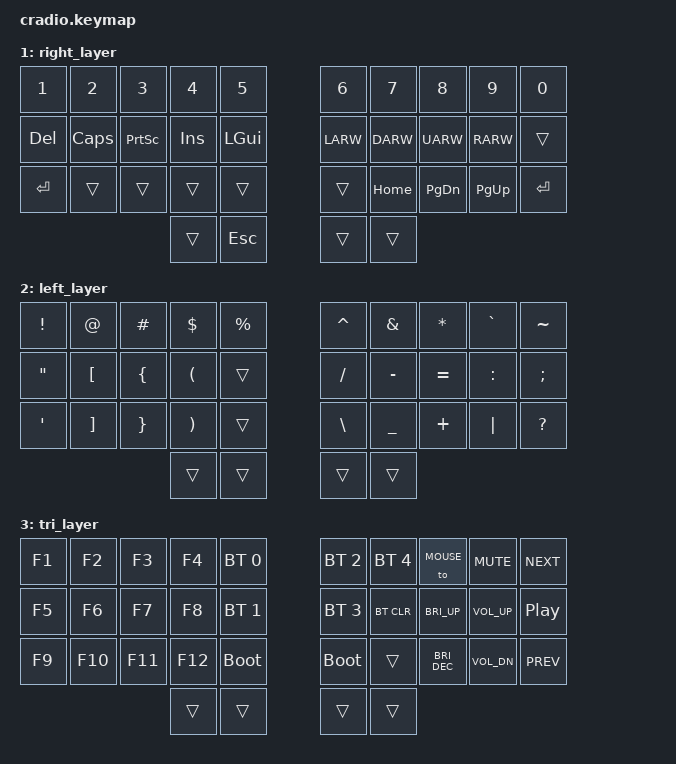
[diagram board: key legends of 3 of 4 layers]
#include <behaviors.dtsi>
#include <dt-bindings/zmk/keys.h>
#include <dt-bindings/zmk/bt.h>
#include <dt-bindings/zmk/mouse.h>

#include "../zmk-nodefree-config/helper.h"
#include "../zmk-nodefree-config/keypos_def/keypos_34keys.h"

#define HRML(k2,k3,k4) &ht LALT k2  &ht LCTRL k3  &ht LGUI k4
#define HRMR(k1,k2,k3) &ht RGUI k1  &ht RCTRL k2  &ht RALT k3
#define WHRML(k2,k3,k4) &ht LALT k2  &ht LGUI k3  &ht LCTRL k4
#define WHRMR(k1,k2,k3) &ht RCTRL k1  &ht RGUI k2  &ht RALT k3

#define WIN 0
#define RIG 1
#define LEF 2
#define TRI 3
#define MOUSE 4

/* layer and key shortcuts */

/ {
  combos {
    compatible = "zmk,combos";
    combo_tab {
      timeout-ms = <50>;
	    key-positions = <1 2>;
      bindings = <&kp TAB>;
     };
    combo_esc {
      timeout-ms = <50>;
	    key-positions = <11 12>;
      bindings = <&kp ESC>;
     };
     combo_lalt {
      timeout-ms = <50>;
      key-positions = <0 1>;
      bindings = <&sk LALT>;
     };
    combo_lctrl {
      timeout-ms = <50>;
	    key-positions = <10 11>;
      bindings = <&sk LCTRL>;
     };
     combo_lgui {
      timeout-ms = <50>;
	    key-positions = <20 21>;
      bindings = <&sk LGUI>;
     };
     combo_setting {
       timeout-ms = <50>;
	     key-positions = <20 21 22>;
       bindings = <&mo 4>;
     };
     combo_rsetting {
       timeout-ms = <50>;
	 key-positions = <27 28 29>;
       bindings = <&mo 4>;
     };
     combo_del {
      timeout-ms = <50>;
	    key-positions = <7 8>;
      bindings = <&kp DELETE>;
     };
     combo_back_space {
      timeout-ms = <50>;
	    key-positions = <17 18>;
      bindings = <&kp BSPC>;
     };
     combo_enter {
      timeout-ms = <50>;
	    key-positions = <27 28>;
      bindings = <&kp RETURN>;
     };
     combo_ralt {
      timeout-ms = <50>;
      key-positions = <8 9>;
      bindings = <&sk RALT>;
     };
     combo_rctrl {
      timeout-ms = <50>;
      key-positions = <18 19>;
      bindings = <&sk RCTRL>;
     };
     combo_rgui {
      timeout-ms = <50>;
	    key-positions = <28 29>;
      bindings = <&sk RGUI>;
     };
     combo_slash {
      timeout-ms = <50>;
	    key-positions = <12 13>;
      bindings = <&kp FSLH>;
     };
     combo_alt_h {
      timeout-ms = <50>;
	    key-positions = <14 24>;
      bindings = <&kp LA(H)>;
     };
     combo_semi {
      timeout-ms = <50>;
	    key-positions = <6 7>;
      bindings = <&kp SEMI>;
     };
     combo_col {
      timeout-ms = <50>;
	    key-positions = <16 17>;
      bindings = <&kp COLON>;
     };
  };

  behaviors {
        ht: hold_tap {
            label = "hold_tap";
            compatible = "zmk,behavior-hold-tap";
            #binding-cells = <2>;
            flavor = "tap-preferred";
            tapping-term-ms = <220>;
            quick-tap-ms = <150>;
            global-quick-tap;
            bindings = <&kp>, <&kp>;
        };
    };

   conditional_layers {
        compatible = "zmk,conditional-layers";
        tri_layer {
            if-layers = <RIG LEF>;
            then-layer = <TRI>;
        };
    };

  keymap {
      compatible = "zmk,keymap";
                
        default_layer {
            bindings = <
        //╭──────────┬──────────┬──────────┬──────────┬──────────╮   ╭──────────┬──────────┬──────────┬──────────┬──────────╮
        //│  Q       │  W       │  E       │  R       │  T       │   │  Y       │  U       │  I       │  O       │  P       │
            &kp Q      WHRML(W ,   E  ,       R  )       &kp T          &kp Y     WHRMR( U,   I ,   O )  &kp P
        //├──────────┼──────────┼──────────┼──────────┼──────────┤   ├──────────┼──────────┼──────────┼──────────┼──────────┤
        //│  A       │  S       │  D       │  F       │  G       │   │  H       │  J       │  K       │  L       │BACKSPACE │
            &kp A        &kp S     &kp  D     &kp  F     &kp G          &kp H      &kp J      &kp  K    &kp L      &kp BSPC
        //├──────────┼──────────┼──────────┼──────────┼──────────┤   ├──────────┼──────────┼──────────┼──────────┼──────────┤
        //│  Z       │  X       │  C       │  V       │  B       │   │  N       │  M       │ , <      │ . >      │   / ?    │
            &kp Z      &kp X      &kp C      &kp V      &kp B          &kp N      &kp M      &kp COMMA  &kp DOT    &kp FSLH
        //╰──────────┴──────────┴──────────┼──────────┼──────────┤   ├──────────┼──────────┼──────────┴──────────┴──────────╯
                                           &lt LEF TAB  &kp LSHIFT    &kp SPACE  &lt RIG TAB
        //                                 ╰──────────┴──────────╯   ╰──────────┴──────────╯
            >;
        };

        right_layer {
            bindings = <
        //╭──────────┬──────────┬──────────┬──────────┬──────────╮   ╭──────────┬──────────┬──────────┬──────────┬──────────╮
        //│ 1        │  2       │  3       │  4       │  5       │   │ 6        │ 7        │ 8        │ 9        │   0      │
            &kp N1    &kp N2     &kp N3     &kp N4     &kp N5          &kp N6     &kp N7     &kp N8     &kp N9      &kp N0
        //├──────────┼──────────┼──────────┼──────────┼──────────┤   ├──────────┼──────────┼──────────┼──────────┼──────────┤
        //│ DELETE   │ CapsLock │ PrintSc  │  INSERT  │          |   | LEFT     │ DOWN     │ UP       │ RIGHT    │          |
            &kp DEL    &kp CAPS	  &kp PSCRN   &kp INS   &kp LGUI       &kp LARW  &kp DARW  &kp  UARW   &kp RARW     &trans
        //├──────────┼──────────┼──────────┼──────────┼──────────┤   ├──────────┼──────────┼──────────┼──────────┼──────────┤
        //│          │          │          │          │          │   │          │ HOME     │ PAGE DN  │ PAGE UP  │ ENTER    │
            &kp ENTER    &trans     &trans     &trans      &trans           &trans   &kp HOME   &kp PG_DN  &kp PG_UP  &kp ENTER 
        //╰──────────┴──────────┴──────────┼──────────┼──────────┤   ├──────────┼──────────┼──────────┴──────────┴──────────╯
                                             &trans     &kp ESC        &trans     &trans
        //                                 ╰──────────┴──────────╯   ╰──────────┴──────────╯
            >;
        };

        left_layer {
            bindings = <
        //╭──────────┬──────────┬──────────┬──────────┬──────────╮   ╭──────────┬──────────┬──────────┬──────────┬──────────╮
        //│  !       │  @       │  #       │  $       │  %       │   │  ^       │  &       │  *       │  `       │  ~       │
            &kp EXCL   &kp AT     &kp HASH   &kp DLLR   &kp PRCNT      &kp CARET  &kp AMPS   &kp ASTRK  &kp GRAVE   &kp TILDE
        //├──────────┼──────────┼──────────┼──────────┼──────────┤   ├──────────┼──────────┼──────────┼──────────┼──────────┤
        //│  "       │  [       │  {       │  (       │          │   │   /      │  -       │  =       │     :    │  ;       │
            &kp DQT  &kp LBKT   &kp LBRC   &kp LPAR      &trans         &kp FSLH   &kp MINUS  &kp EQUAL  &kp COLON   &kp SEMI
        //├──────────┼──────────┼──────────┼──────────┼──────────┤   ├──────────┼──────────┼──────────┼──────────┼──────────┤
        //│  '       │  ]       │  }       │  )       │          │   │    \     │  _       │  +       │  │       │   ?      │
            &kp SQT     &kp RBKT   &kp RBRC   &kp RPAR   &trans         &kp BSLH   &kp UNDER  &kp PLUS   &kp PIPE  &kp QMARK
        //╰──────────┴──────────┴──────────┼──────────┼──────────┤   ├──────────┼──────────┼──────────┴──────────┴──────────╯
                                             &trans     &trans         &trans     &trans
        //                                 ╰──────────┴──────────╯   ╰──────────┴──────────╯
            >;
        };

        tri_layer {
            bindings = <
        //╭──────────┬──────────┬──────────┬───────────┬────────────╮   ╭────────────┬────────────┬──────────┬───────────┬──────────╮
        //│  F1      │  F2      │  F3      │  F4       │ PROFILE 0  │   │ PROFILE 2  │            │ MOUSE  │ VOL MUTE  │ NEXTSONG │
            &kp F1     &kp F2     &kp F3     &kp F4     &bt BT_SEL 0     &bt BT_SEL 2 &bt BT_SEL 4  &to MOUSE  &kp C_MUTE  &kp C_NEXT
        //├──────────┼──────────┼──────────┼───────────┼────────────┤   ├────────────┼────────────┼──────────┼───────────┼──────────┤
        //│  F5      │  F6      │  F7      │  F8       │ PROFILE 1  │   │ PROFILE 3  │            │INC BRIGHT │ VOL UP   │PAUSEMUSIC│
            &kp F5     &kp F6     &kp F7     &kp F8     &bt BT_SEL 1     &bt BT_SEL 3 &bt BT_CLR   &kp C_BRI_UP   &kp C_VOL_UP  &kp C_PP
        //├──────────┼──────────┼──────────┼───────────┼────────────┤   ├────────────┼────────────┼──────────┼───────────┼──────────┤
            &kp F9     &kp F10    &kp F11    &kp F12      &bootloader     &bootloader  &trans      &kp C_BRI_DEC  &kp C_VOL_DN &kp C_PREV
        //╰──────────┴──────────┴──────────┼───────────┼────────────┤   ├────────────┼────────────┼──────────┴───────────┴──────────╯
                                                &trans     &trans         &trans     &trans
        //                                  ╰───────────┴──────────╯   ╰──────────┴────────────╯
            >;
        };

   
  // MOUSE layer
  //  mouse_layer {
	//  bindings = <
  //        &kp PG_UP  &kp HOME  &kp UP &kp END &kp CAPS 		                        &kp ESC            &mkp LCLK        &mkp MCLK       &mkp RCLK         &mkp MCLK 
  //        &kp LEFT   &kp DOWN  &kp UP &kp RIGHT &kp ENTER  	                      &mmv MOVE_LEFT     &mmv MOVE_DOWN   &mmv MOVE_UP    &mmv MOVE_RIGHT   &mkp LCLK
  //        &mkp LCLK  &mkp MCLK  &mkp RCLK &kp K_VOL_UP  &kp K_VOL_DN              &mwh SCROLL_LEFT   &mwh SCROLL_DOWN &mwh SCROLL_UP  &mwh SCROLL_RIGHT &mkp RCLK
  //                                             &to 0     &trans                        &trans     &to 0
  //      >;
	//};	

  };
};
